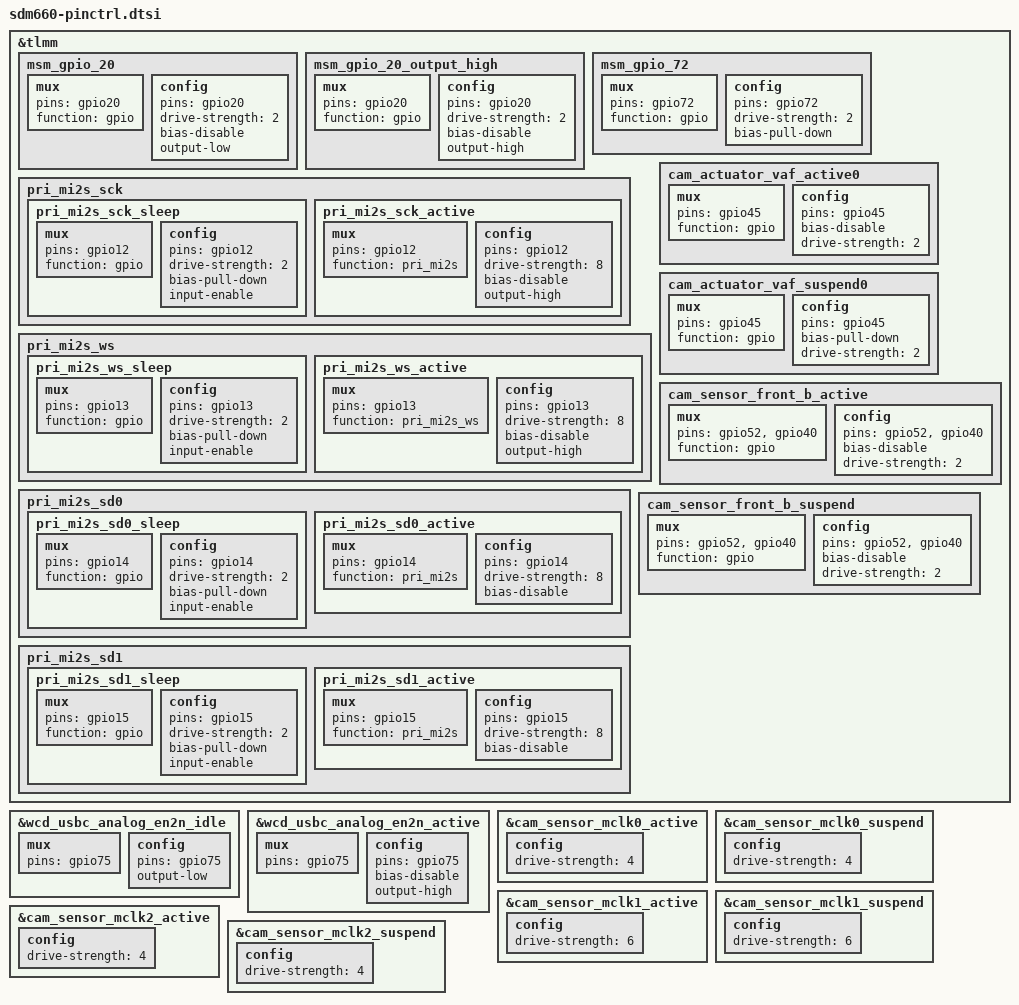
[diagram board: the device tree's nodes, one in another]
&tlmm {
	msm_gpio_20: msm_gpio_20 {
		mux {
			pins="gpio20";
			function= "gpio";
		};

		config {
			pins= "gpio20";
			drive-strength = <2>;
			bias-disable;
			output-low;
		};
	};

	msm_gpio_20_output_high: msm_gpio_20_output_high {
		mux {
			pins = "gpio20";
			function = "gpio";
		};

		config {
			pins = "gpio20";
			drive-strength = <2>;
			bias-disable;
			output-high;
		};
	};

	msm_gpio_72: msm_gpio_72 {
		mux {
			pins = "gpio72";
			function = "gpio";
		};

		config {
			pins = "gpio72";
			drive-strength=<2>;
			bias-pull-down;
		};
	};

	pri_mi2s_sck {
		pri_mi2s_sck_sleep: pri_mi2s_sck_sleep {
			mux {
				pins = "gpio12";
				function = "gpio";
			};

			config {
				pins = "gpio12";
				drive-strength = <2>;
				bias-pull-down;
				input-enable;
			};
		};

		pri_mi2s_sck_active: pri_mi2s_sck_active {
			mux {
				pins = "gpio12";
				function = "pri_mi2s";
			};

			config {
				pins = "gpio12";
				drive-strength = <8>;
				bias-disable;
				output-high;
			};
		};
	};

	pri_mi2s_ws {
		pri_mi2s_ws_sleep: pri_mi2s_ws_sleep {
			mux {
				pins = "gpio13";
				function = "gpio";
			};

			config {
				pins = "gpio13";
				drive-strength = <2>;
				bias-pull-down;
				input-enable;
			};
		};

		pri_mi2s_ws_active: pri_mi2s_ws_active {
			mux {
				pins = "gpio13";
				function = "pri_mi2s_ws";
			};

			config {
				pins = "gpio13";
				drive-strength = <8>;
				bias-disable;
				output-high;
			};
		};
	};

	pri_mi2s_sd0 {
		pri_mi2s_sd0_sleep: pri_mi2s_sd0_sleep {
			mux {
				pins = "gpio14";
				function = "gpio";
			};

			config {
				pins = "gpio14";
				drive-strength = <2>;
				bias-pull-down;
				input-enable;
			};
		};

		pri_mi2s_sd0_active: pri_mi2s_sd0_active {
			mux {
				pins = "gpio14";
				function = "pri_mi2s";
			};

			config {
				pins = "gpio14";
				drive-strength = <8>;
				bias-disable;
			};
		};
	};

	pri_mi2s_sd1 {
		pri_mi2s_sd1_sleep: pri_mi2s_sd1_sleep {
			mux {
				pins = "gpio15";
				function = "gpio";
			};

			config {
				pins = "gpio15";
				drive-strength = <2>;
				bias-pull-down;
				input-enable;
			};
		};

		pri_mi2s_sd1_active: pri_mi2s_sd1_active {
			mux {
				pins = "gpio15";
				function = "pri_mi2s";
			};

			config {
				pins = "gpio15";
				drive-strength = <8>;
				bias-disable;
			};
		};
	};

	cam_actuator_vaf_active0: cam_actuator_vaf_active0 {
		mux {
			pins = "gpio45";
			function = "gpio";
		};

		config {
			pins = "gpio45";
			bias-disable;
			drive-strength = <2>;
		};
	};

	cam_actuator_vaf_suspend0: cam_actuator_vaf_suspend0 {
		mux {
			pins = "gpio45";
			function = "gpio";
		};

		config {
			pins = "gpio45";
			bias-pull-down;
			drive-strength = <2>;
		};
	};

	cam_sensor_front_b_active: cam_sensor_front_b_active {
		mux {
			pins = "gpio52","gpio40";
			function = "gpio";
		};

		config {
			pins = "gpio52","gpio40";
			bias-disable;
			drive-strength = <2>;
		};
	};

	cam_sensor_front_b_suspend: cam_sensor_front_b_suspend {
		mux {
			pins = "gpio52","gpio40";
			function = "gpio";
		};

		config {
			pins = "gpio52","gpio40";
			bias-disable;
			drive-strength = <2>;
		};
	};
};

&wcd_usbc_analog_en2n_idle {
	mux {
		pins = "gpio75";
	};

	config {
		pins = "gpio75";
		/delete-property/ output-high;
		output-low;
	};
};

&wcd_usbc_analog_en2n_active {
	mux {
		pins = "gpio75";
	};

	config {
		pins = "gpio75";
		bias-disable;
		/delete-property/ bias-pull-down;
		output-high;
		/delete-property/ output-low;
	};
};

&cam_sensor_mclk0_active {
	config {
		drive-strength = <4>;
	};
};

&cam_sensor_mclk0_suspend {
	config {
		drive-strength = <4>;
	};
};

&cam_sensor_mclk1_active {
	config {
		drive-strength = <6>;
	};
};

&cam_sensor_mclk1_suspend {
	config {
		drive-strength = <6>;
	};
};

&cam_sensor_mclk2_active {
	config {
		drive-strength = <4>;
	};
};

&cam_sensor_mclk2_suspend {
	config {
		drive-strength = <4>;
	};
};
